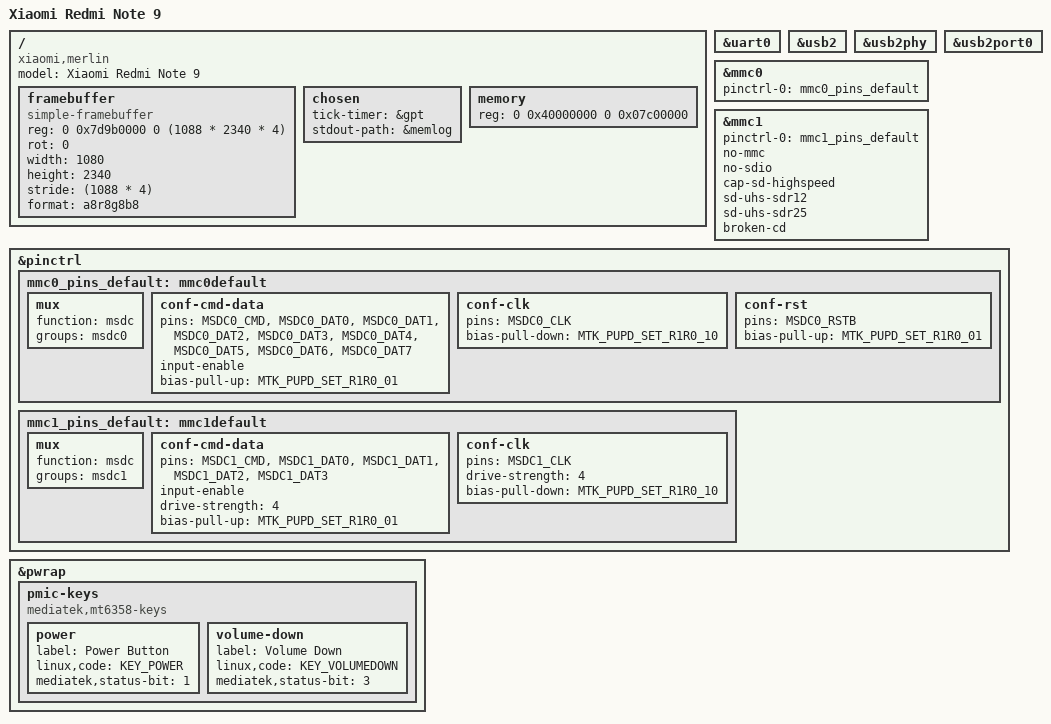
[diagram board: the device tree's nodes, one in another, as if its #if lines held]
/dts-v1/;
#include <config.h>

#include <dt-bindings/input/input.h>
#include "mt6768.dtsi"
#include "skeleton64.dtsi"

/ {
#if defined(CONFIG_XIAOMI_MERLIN)
    model = "Xiaomi Redmi Note 9";
    compatible = "xiaomi,merlin";

    framebuffer {
        compatible = "simple-framebuffer";
        reg = <0 0x7d9b0000 0 (1088 * 2340 * 4)>;
        rot = <0>;
        width = <1080>;
        height = <2340>;
        stride = <(1088 * 4)>;
        format = "a8r8g8b8";
        status = "okay";
    };
#elif defined(CONFIG_XIAOMI_LANCELOT)
    model = "Xiaomi Redmi 9";
    compatible = "xiaomi,lancelot";

    /*
     * Console into RAM. There is no reachable UART on this phone, so without
     * this a U-Boot that hangs before video is up leaves nothing to debug.
     * Sits past the end of what /dev/fb0 maps, inside the framebuffer
     * reservation, where neither lk nor Linux writes.
     */
    memlog: serial-memlog {
        compatible = "u-boot,serial-memlog";
        /* bind before relocation, else the console dies right after DRAM */
        bootph-all;
        status = "okay";
    };

    fb0: framebuffer {
        compatible = "simple-framebuffer";
        reg = <0 0x7dcb0000 0 (1088 * 2340 * 4)>;
        rot = <0>;
        width = <1080>;
        height = <2340>;
        stride = <(1088 * 4)>;
        format = "a8r8g8b8";
        status = "okay";
    };
#elif defined(CONFIG_MOTOROLA_LAMUC)
    model = "Motorola Moto G17";
    compatible = "motorola,lamuc";

    /* lk's address from its log; dram_init() replaces it from lk's FDT */
    fb0: framebuffer {
        compatible = "simple-framebuffer";
        reg = <0 0x77916000 0 (1080 * 2400 * 4)>;
        rot = <0>;
        width = <1080>;
        height = <2400>;
        /* scan-out pitch is packed, unlike lk's 32-pixel aligned page size */
        stride = <(1080 * 4)>;
        format = "a8r8g8b8";
        status = "okay";
    };

    /* status-bit: KP_MEM1 bit for the keypad, TOPSTATUS bit for the PMIC */
    keypad@10010000 {
        compatible = "mediatek,mt6768-keypad";
        reg = <0 0x10010000 0 0x1000>;

        volume-up {
            label = "Volume Up";
            linux,code = <KEY_VOLUMEUP>;
            mediatek,status-bit = <0>;
        };
    };
#else
    model = "MediaTek MT6768-based device";
    compatible = "generic,mt6768";
#endif

    chosen {
        tick-timer = &gpt;
#if defined(CONFIG_XIAOMI_LANCELOT)
        stdout-path = &memlog;
#endif
    };

    /*
     * The name must be `memory` with no unit address: skeleton64.dtsi already
     * declares `/memory` with reg = <0 0 0 0>, and U-Boot looks up the exact
     * path "/memory". Naming it `memory@40000000` would create a second node
     * and U-Boot would still read the empty one.
     */
    memory {
        /*
         * Declare only the first contiguous region: 0x40000000 to 0x7dcb0000,
         * where the framebuffer reservation begins. U-Boot relocates to the
         * top of this region, so it has to be certain that it is real RAM.
         */
#if defined(CONFIG_MOTOROLA_LAMUC)
        /* lk's layout is unknown here: stay below the ramdisk at 0x47c80000 */
        reg = <0 0x40000000 0 0x07c00000>;
#else
        reg = <0 0x40000000 0 0x3dcb0000>;
#endif
        device_type = "memory";
    };
};

&uart0 {
    status = "okay";
};

&usb2 {
    status = "okay";
};

&usb2phy {
    status = "okay";
};

&usb2port0 {
    status = "okay";
};

&mmc0 {
    pinctrl-names = "default";
    pinctrl-0 = <&mmc0_pins_default>;
    status = "okay";
};

&mmc1 {
	pinctrl-names = "default";
	pinctrl-0 = <&mmc1_pins_default>;
	status = "okay";
	//bus-width = <4>;
	//max-frequency = <50000000>;
	no-mmc;
	no-sdio;
	cap-sd-highspeed;
	//sd-uhs-ddr50;
	//sd-uhs-sdr104;
	sd-uhs-sdr12;
	sd-uhs-sdr25;
    	broken-cd;
};

&pinctrl {
	mmc0_pins_default: mmc0default {
		mux {
			function = "msdc";
			groups = "msdc0";
		};

		conf-cmd-data {
			pins = "MSDC0_CMD", "MSDC0_DAT0", "MSDC0_DAT1",
			       "MSDC0_DAT2", "MSDC0_DAT3", "MSDC0_DAT4",
			       "MSDC0_DAT5", "MSDC0_DAT6", "MSDC0_DAT7";
			input-enable;
			bias-pull-up = <MTK_PUPD_SET_R1R0_01>;
		};

		conf-clk {
			pins = "MSDC0_CLK";
			bias-pull-down = <MTK_PUPD_SET_R1R0_10>;
		};

		conf-rst {
			pins = "MSDC0_RSTB";
			bias-pull-up = <MTK_PUPD_SET_R1R0_01>;
		};
	};

	mmc1_pins_default: mmc1default {
		mux {
			function = "msdc";
			groups = "msdc1";
		};

		conf-cmd-data {
			pins = "MSDC1_CMD", "MSDC1_DAT0", "MSDC1_DAT1",
			       "MSDC1_DAT2", "MSDC1_DAT3";
			input-enable;
			drive-strength = <4>;
			bias-pull-up = <MTK_PUPD_SET_R1R0_01>;
		};

		conf-clk {
			pins = "MSDC1_CLK";
			drive-strength = <4>;
			bias-pull-down = <MTK_PUPD_SET_R1R0_10>;
		};
	};
};

#if defined(CONFIG_MOTOROLA_LAMUC)
&pwrap {
    pmic-keys {
        compatible = "mediatek,mt6358-keys";

        power {
            label = "Power Button";
            linux,code = <KEY_POWER>;
            mediatek,status-bit = <1>;
        };

        volume-down {
            label = "Volume Down";
            linux,code = <KEY_VOLUMEDOWN>;
            mediatek,status-bit = <3>;
        };
    };
};
#endif
